AUTOSAR XML (schema 4-0-3)
standard types defined: Boolean, UInt16, UInt32
package /AUTOSAR_Platform/DataConstrs
  range DC_Boolean: raw 0..1
  range DC_UInt16: raw 0..65535
package /PATAC/Facility/DataTypes/Implementation
  compu method COMPU_Boolean: 0=FALSE, 1=TRUE
  unit NoUnit: factor-si-to-unit=1, offset-si-to-unit=0
package /PATAC/MSM/ComponentTypes
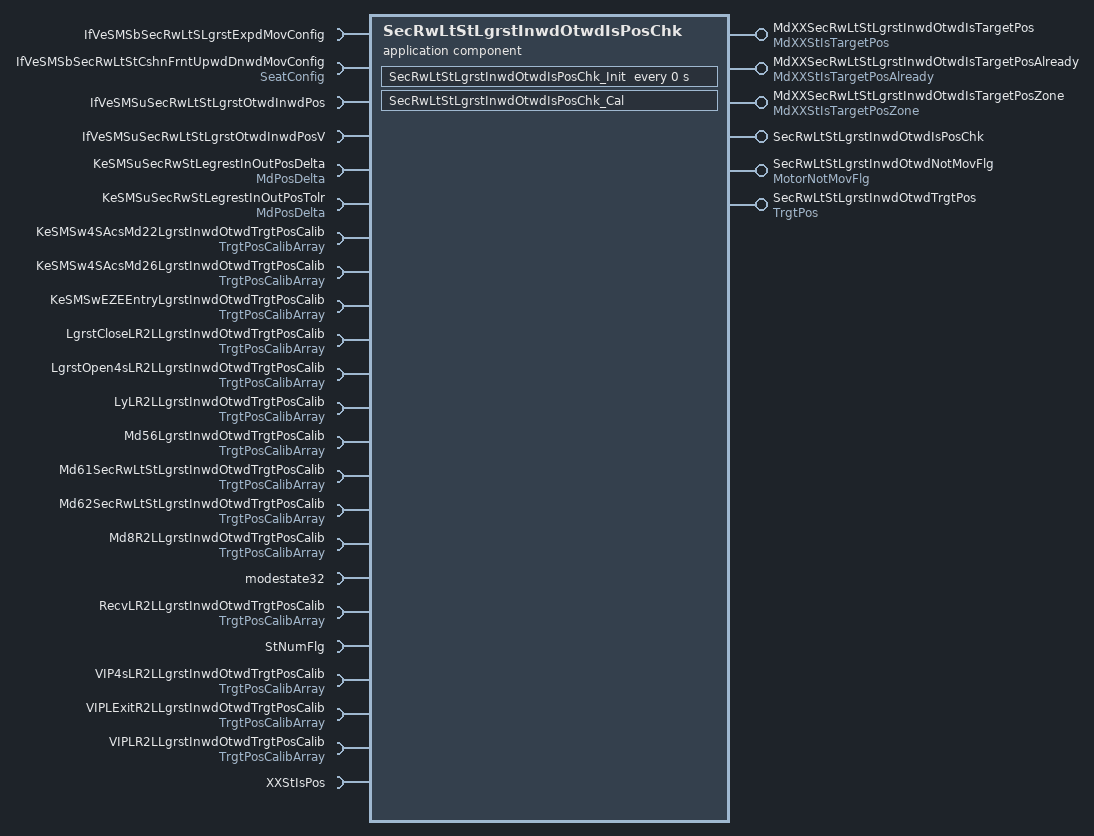
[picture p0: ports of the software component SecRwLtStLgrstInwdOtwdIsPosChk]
  application sw component type SecRwLtStLgrstInwdOtwdIsPosChk
    6 x provide port:
      MdXXSecRwLtStLgrstInwdOtwdIsTargetPos: nonqueued-sender-com-spec=data-element=MdXXStIsTargetPos/Val, provided-interface=MdXXStIsTargetPos
      MdXXSecRwLtStLgrstInwdOtwdIsTargetPosAlready: nonqueued-sender-com-spec=data-element=MdXXStIsTargetPosAlready/Val, provided-interface=MdXXStIsTargetPosAlready
      MdXXSecRwLtStLgrstInwdOtwdIsTargetPosZone: nonqueued-sender-com-spec=data-element=MdXXStIsTargetPosZone/Val, provided-interface=MdXXStIsTargetPosZone
      SecRwLtStLgrstInwdOtwdIsPosChk: server-com-spec{operation=Cal, queue-length=1}, provided-interface=SecRwLtStLgrstInwdOtwdIsPosChk
      SecRwLtStLgrstInwdOtwdNotMovFlg: nonqueued-sender-com-spec{data-element=MotorNotMovFlg/Val, init-value=0}, provided-interface=MotorNotMovFlg
      SecRwLtStLgrstInwdOtwdTrgtPos: nonqueued-sender-com-spec{data-element=TrgtPos/Val, init-value=4095}, provided-interface=TrgtPos
    23 x require port:
      IfVeSMSbSecRwLtSLgrstExpdMovConfig: nonqueued-receiver-com-spec{data-element=IfVeSMSbSecRwLtSLgrstExpdMovConfig/Val, filter=data-filter-type=ALWAYS, init-value=1}, required-interface=IfVeSMSbSecRwLtSLgrstExpdMovConfig
      IfVeSMSbSecRwLtStCshnFrntUpwdDnwdMovConfig: nonqueued-receiver-com-spec{data-element=SeatConfig/Val, filter=data-filter-type=ALWAYS, init-value=0}, required-interface=SeatConfig
      IfVeSMSuSecRwLtStLgrstOtwdInwdPos: nonqueued-receiver-com-spec{data-element=IfVeSMSuSecRwLtStLgrstOtwdInwdPos/Val, filter=data-filter-type=ALWAYS, init-value=0}, required-interface=IfVeSMSuSecRwLtStLgrstOtwdInwdPos
      IfVeSMSuSecRwLtStLgrstOtwdInwdPosV: nonqueued-receiver-com-spec{data-element=IfVeSMSuSecRwLtStLgrstOtwdInwdPosV/Val, filter=data-filter-type=ALWAYS, init-value=0}, required-interface=IfVeSMSuSecRwLtStLgrstOtwdInwdPosV
      KeSMSuSecRwStLegrestInOutPosDelta: parameter-require-com-spec{init-value=150, parameter=Val}, required-interface=MdPosDelta
      KeSMSuSecRwStLegrestInOutPosTolr: parameter-require-com-spec{init-value=150, parameter=Val}, required-interface=MdPosDelta
      KeSMSw4SAcsMd22LgrstInwdOtwdTrgtPosCalib: nonqueued-receiver-com-spec{data-element=TrgtPosArray, filter=data-filter-type=ALWAYS, init-value=[4095, 4095, 4095]}, required-interface=TrgtPosCalibArray
      KeSMSw4SAcsMd26LgrstInwdOtwdTrgtPosCalib: nonqueued-receiver-com-spec{data-element=TrgtPosArray, filter=data-filter-type=ALWAYS, init-value=[4095, 4095, 4095]}, required-interface=TrgtPosCalibArray
      KeSMSwEZEEntryLgrstInwdOtwdTrgtPosCalib: nonqueued-receiver-com-spec{data-element=TrgtPosArray, filter=data-filter-type=ALWAYS, init-value=[4095, 4095, 4095]}, required-interface=TrgtPosCalibArray
      LgrstCloseLR2LLgrstInwdOtwdTrgtPosCalib: nonqueued-receiver-com-spec{data-element=TrgtPosArray, filter=data-filter-type=ALWAYS, init-value=[4095, 4095, 4095]}, required-interface=TrgtPosCalibArray
      LgrstOpen4sLR2LLgrstInwdOtwdTrgtPosCalib: nonqueued-receiver-com-spec{data-element=TrgtPosArray, filter=data-filter-type=ALWAYS, init-value=[4095, 4095, 4095]}, required-interface=TrgtPosCalibArray
      LyLR2LLgrstInwdOtwdTrgtPosCalib: nonqueued-receiver-com-spec{data-element=TrgtPosArray, filter=data-filter-type=ALWAYS, init-value=[4095, 4095, 4095]}, required-interface=TrgtPosCalibArray
      Md56LgrstInwdOtwdTrgtPosCalib: nonqueued-receiver-com-spec{data-element=TrgtPosArray, filter=data-filter-type=ALWAYS, init-value=[4095, 4095, 4095]}, required-interface=TrgtPosCalibArray
      Md61SecRwLtStLgrstInwdOtwdTrgtPosCalib: nonqueued-receiver-com-spec{data-element=TrgtPosArray, filter=data-filter-type=ALWAYS, init-value=[4095, 4095, 4095]}, required-interface=TrgtPosCalibArray
      Md62SecRwLtStLgrstInwdOtwdTrgtPosCalib: nonqueued-receiver-com-spec{data-element=TrgtPosArray, filter=data-filter-type=ALWAYS, init-value=[4095, 4095, 4095]}, required-interface=TrgtPosCalibArray
      Md8R2LLgrstInwdOtwdTrgtPosCalib: nonqueued-receiver-com-spec{data-element=TrgtPosArray, filter=data-filter-type=ALWAYS, init-value=[4095, 4095, 4095]}, required-interface=TrgtPosCalibArray
      modestate32: nonqueued-receiver-com-spec{data-element=modestate32/Val, filter=data-filter-type=ALWAYS, init-value=0}, required-interface=modestate32
      RecvLR2LLgrstInwdOtwdTrgtPosCalib: nonqueued-receiver-com-spec{data-element=TrgtPosArray, filter=data-filter-type=ALWAYS, init-value=[4095, 4095, 4095]}, required-interface=TrgtPosCalibArray
      StNumFlg: required-interface=StNumFlg
        required-com-specs:
          data-element=Is4s, filter=data-filter-type=ALWAYS, init-value=0
          data-element=Is6s, filter=data-filter-type=ALWAYS, init-value=0
          data-element=Is6s7s, filter=data-filter-type=ALWAYS, init-value=0
          data-element=Is7s, filter=data-filter-type=ALWAYS, init-value=0
      VIP4sLR2LLgrstInwdOtwdTrgtPosCalib: nonqueued-receiver-com-spec{data-element=TrgtPosArray, filter=data-filter-type=ALWAYS, init-value=[4095, 4095, 4095]}, required-interface=TrgtPosCalibArray
      VIPLExitR2LLgrstInwdOtwdTrgtPosCalib: nonqueued-receiver-com-spec{data-element=TrgtPosArray, filter=data-filter-type=ALWAYS, init-value=[4095, 4095, 4095]}, required-interface=TrgtPosCalibArray
      VIPLR2LLgrstInwdOtwdTrgtPosCalib: nonqueued-receiver-com-spec{data-element=TrgtPosArray, filter=data-filter-type=ALWAYS, init-value=[4095, 4095, 4095]}, required-interface=TrgtPosCalibArray
      XXStIsPos: client-com-spec=Get, required-interface=XXStIsPos
    behavior SecRwLtStLgrstInwdOtwdIsPosChk_InternalBehavior
      operation invoked event OIT_SecRwLtStLgrstInwdOtwdIsPosChk_Cal_SecRwLtStLgrstInwdOtwdIsPosChk_Cal: start-on-event=SecRwLtStLgrstInwdOtwdIsPosChk_Cal, operation=SecRwLtStLgrstInwdOtwdIsPosChk.Cal
      timing event SecRwLtStLgrstInwdOtwdIsPosChk_InitEvent: start-on-event=SecRwLtStLgrstInwdOtwdIsPosChk_Init, period=0
      runnable SecRwLtStLgrstInwdOtwdIsPosChk_Cal
        data-receive-point-by-arguments:
          23 x access:
            REC_IfVeSMSbSecRwLtSLgrstExpdMovConfig_Val: accessed-variable=IfVeSMSbSecRwLtSLgrstExpdMovConfig.Val
            REC_IfVeSMSbSecRwLtStCshnFrntUpwdDnwdMovConfig_Val: accessed-variable=IfVeSMSbSecRwLtStCshnFrntUpwdDnwdMovConfig.Val
            REC_IfVeSMSuSecRwLtStLgrstOtwdInwdPos_Val: accessed-variable=IfVeSMSuSecRwLtStLgrstOtwdInwdPos.Val
            REC_IfVeSMSuSecRwLtStLgrstOtwdInwdPosV_Val: accessed-variable=IfVeSMSuSecRwLtStLgrstOtwdInwdPosV.Val
            REC_KeSMSw4SAcsMd22LgrstInwdOtwdTrgtPosCalib_TrgtPosArray: accessed-variable=KeSMSw4SAcsMd22LgrstInwdOtwdTrgtPosCalib.TrgtPosArray
            REC_KeSMSw4SAcsMd26LgrstInwdOtwdTrgtPosCalib_TrgtPosArray: accessed-variable=KeSMSw4SAcsMd26LgrstInwdOtwdTrgtPosCalib.TrgtPosArray
            REC_KeSMSwEZEEntryLgrstInwdOtwdTrgtPosCalib_TrgtPosArray: accessed-variable=KeSMSwEZEEntryLgrstInwdOtwdTrgtPosCalib.TrgtPosArray
            REC_LgrstCloseLR2LLgrstInwdOtwdTrgtPosCalib_TrgtPosArray: accessed-variable=LgrstCloseLR2LLgrstInwdOtwdTrgtPosCalib.TrgtPosArray
            REC_LgrstOpen4sLR2LLgrstInwdOtwdTrgtPosCalib_TrgtPosArray: accessed-variable=LgrstOpen4sLR2LLgrstInwdOtwdTrgtPosCalib.TrgtPosArray
            REC_LyLR2LLgrstInwdOtwdTrgtPosCalib_TrgtPosArray: accessed-variable=LyLR2LLgrstInwdOtwdTrgtPosCalib.TrgtPosArray
            REC_Md56LgrstInwdOtwdTrgtPosCalib_TrgtPosArray: accessed-variable=Md56LgrstInwdOtwdTrgtPosCalib.TrgtPosArray
            REC_Md61SecRwLtStLgrstInwdOtwdTrgtPosCalib_TrgtPosArray: accessed-variable=Md61SecRwLtStLgrstInwdOtwdTrgtPosCalib.TrgtPosArray
            REC_Md62SecRwLtStLgrstInwdOtwdTrgtPosCalib_TrgtPosArray: accessed-variable=Md62SecRwLtStLgrstInwdOtwdTrgtPosCalib.TrgtPosArray
            REC_Md8R2LLgrstInwdOtwdTrgtPosCalib_TrgtPosArray: accessed-variable=Md8R2LLgrstInwdOtwdTrgtPosCalib.TrgtPosArray
            REC_modestate32_Val: accessed-variable=modestate32.Val
            REC_RecvLR2LLgrstInwdOtwdTrgtPosCalib_TrgtPosArray: accessed-variable=RecvLR2LLgrstInwdOtwdTrgtPosCalib.TrgtPosArray
            REC_StNumFlg_Is4s: accessed-variable=StNumFlg.Is4s
            REC_StNumFlg_Is6s: accessed-variable=StNumFlg.Is6s
            REC_StNumFlg_Is6s7s: accessed-variable=StNumFlg.Is6s7s
            REC_StNumFlg_Is7s: accessed-variable=StNumFlg.Is7s
            REC_VIP4sLR2LLgrstInwdOtwdTrgtPosCalib_TrgtPosArray: accessed-variable=VIP4sLR2LLgrstInwdOtwdTrgtPosCalib.TrgtPosArray
            REC_VIPLExitR2LLgrstInwdOtwdTrgtPosCalib_TrgtPosArray: accessed-variable=VIPLExitR2LLgrstInwdOtwdTrgtPosCalib.TrgtPosArray
            REC_VIPLR2LLgrstInwdOtwdTrgtPosCalib_TrgtPosArray: accessed-variable=VIPLR2LLgrstInwdOtwdTrgtPosCalib.TrgtPosArray
        data-send-points:
          5 x access:
            SEND_MdXXSecRwLtStLgrstInwdOtwdIsTargetPos_Val: accessed-variable=MdXXSecRwLtStLgrstInwdOtwdIsTargetPos.Val
            SEND_MdXXSecRwLtStLgrstInwdOtwdIsTargetPosAlready_Val: accessed-variable=MdXXSecRwLtStLgrstInwdOtwdIsTargetPosAlready.Val
            SEND_MdXXSecRwLtStLgrstInwdOtwdIsTargetPosZone_Val: accessed-variable=MdXXSecRwLtStLgrstInwdOtwdIsTargetPosZone.Val
            SEND_SecRwLtStLgrstInwdOtwdNotMovFlg_Val: accessed-variable=SecRwLtStLgrstInwdOtwdNotMovFlg.Val
            SEND_SecRwLtStLgrstInwdOtwdTrgtPos_Val: accessed-variable=SecRwLtStLgrstInwdOtwdTrgtPos.Val
        parameter access PA_KeSMSuSecRwStLegrestInOutPosDelta_Val: accessed-parameter=KeSMSuSecRwStLegrestInOutPosDelta.Val
        parameter access PA_KeSMSuSecRwStLegrestInOutPosTolr_Val: accessed-parameter=KeSMSuSecRwStLegrestInOutPosTolr.Val
        sync call SC_XXStIsPos_Get: operation=XXStIsPos.Get, timeout=0
      runnable SecRwLtStLgrstInwdOtwdIsPosChk_Init
        parameter access PA_KeSMSuSecRwStLegrestInOutPosDelta_Val: accessed-parameter=KeSMSuSecRwStLegrestInOutPosDelta.Val
        parameter access PA_KeSMSuSecRwStLegrestInOutPosTolr_Val: accessed-parameter=KeSMSuSecRwStLegrestInOutPosTolr.Val
  swc implementation SecRwLtStLgrstInwdOtwdIsPosChk_Implementation: behavior=SecRwLtStLgrstInwdOtwdIsPosChk_InternalBehavior
    code-descriptors:
      code Default: artifact-descriptors=autosar-engineering-object={short-label=Default, category=SWSRC}
package /PATAC/MSM/ModeAdjust/CalPortInterface
  parameter interface MdPosDelta
    parameter data prototype Val: sw-calibration-access=READ-WRITE, type=UInt16
package /PATAC/MSM/ModeAdjust/DataType
  impl type TrgtPosCalibArray: category=ARRAY, sw-calibration-access=READ-ONLY, type-emitter=RTE  # 0:pos 1:max 2:min
    element Element: array-size=3, array-size-semantics=FIXED-SIZE, implementation-data-type=UInt16, invalid-value=0
package /PATAC/MSM/ModeAdjust/PortInterface
  client server interface SecRwLtStLgrstInwdOtwdIsPosChk
    operation Cal
  client server interface XXStIsPos
    operation Get
      8 x arg, all with server-argument-impl-policy=USE-ARGUMENT-TYPE:
        PosV: type=DataTypes/Boolean, direction=IN
        Pos: type=UInt16, direction=IN
        CalibArray: type=TrgtPosCalibArray, direction=IN
        Delta: type=UInt16, direction=IN
        Tolr: type=UInt16, direction=IN
        IsPos: type=DataTypes/Boolean, direction=OUT
        IsPosZone: type=DataTypes/Boolean, direction=OUT
        IsPosAlready: type=DataTypes/Boolean, direction=OUT
  7 x sender receiver interface:
    MdXXStIsTargetPos: invalidation-policy{data-element=MdXXStIsTargetPos/Val, handle-invalid=DONT-INVALIDATE}
      data Val: type=UInt32
    MdXXStIsTargetPosAlready: invalidation-policy{data-element=MdXXStIsTargetPosAlready/Val, handle-invalid=DONT-INVALIDATE}
      data Val: type=UInt32
    MdXXStIsTargetPosZone: invalidation-policy{data-element=MdXXStIsTargetPosZone/Val, handle-invalid=DONT-INVALIDATE}
      data Val: type=UInt32
    modestate32: invalidation-policy{data-element=modestate32/Val, handle-invalid=DONT-INVALIDATE}
      data Val: type=UInt32
    MotorNotMovFlg: invalidation-policy{data-element=MotorNotMovFlg/Val, handle-invalid=DONT-INVALIDATE}
      data Val: type=Implementation/Boolean
    StNumFlg
      4 x data, all with type=Implementation/Boolean:
        Is4s
        Is6s
        Is6s7s
        Is7s
      invalidation-policys:
        data-element=Is4s, handle-invalid=DONT-INVALIDATE
        data-element=Is6s, handle-invalid=DONT-INVALIDATE
        data-element=Is6s7s, handle-invalid=DONT-INVALIDATE
        data-element=Is7s, handle-invalid=DONT-INVALIDATE
    TrgtPosCalibArray: invalidation-policy{data-element=TrgtPosArray, handle-invalid=DONT-INVALIDATE}
      data TrgtPosArray: type=TrgtPosCalibArray  # 0:Pos 1:Max 2:Min
package /PATAC/MSM/PortInterfaces
  5 x sender receiver interface:
    IfVeSMSbSecRwLtSLgrstExpdMovConfig: invalidation-policy{data-element=IfVeSMSbSecRwLtSLgrstExpdMovConfig/Val, handle-invalid=DONT-INVALIDATE}
      data Val: type=Implementation/Boolean
    IfVeSMSuSecRwLtStLgrstOtwdInwdPos: invalidation-policy{data-element=IfVeSMSuSecRwLtStLgrstOtwdInwdPos/Val, handle-invalid=DONT-INVALIDATE}
      data Val: type=UInt16
    IfVeSMSuSecRwLtStLgrstOtwdInwdPosV: invalidation-policy{data-element=IfVeSMSuSecRwLtStLgrstOtwdInwdPosV/Val, handle-invalid=DONT-INVALIDATE}
      data Val: type=Implementation/Boolean
    SeatConfig: invalidation-policy{data-element=SeatConfig/Val, handle-invalid=DONT-INVALIDATE}
      data Val: type=Implementation/Boolean
    TrgtPos: invalidation-policy{data-element=TrgtPos/Val, handle-invalid=DONT-INVALIDATE}
      data Val: type=UInt16
